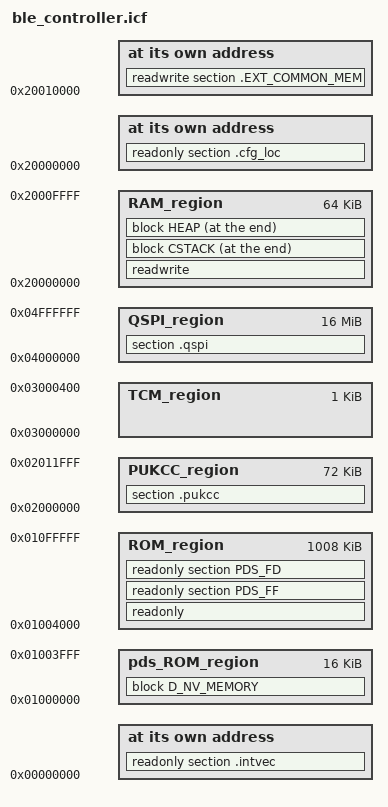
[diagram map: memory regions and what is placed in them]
/**
 * \file
 *
 * \brief Linker script for running in internal SRAM on the Liberty
 *
 * Copyright (c) 2017 Atmel Corporation,
 *                    a wholly owned subsidiary of Microchip Technology Inc.
 *
 * \asf_license_start
 *
 * \page License
 *
 * Licensed under the Apache License, Version 2.0 (the "License");
 * you may not use this file except in compliance with the License.
 * You may obtain a copy of the Licence at
 *
 *     http://www.apache.org/licenses/LICENSE-2.0
 *
 * Unless required by applicable law or agreed to in writing, software
 * distributed under the License is distributed on an "AS IS" BASIS,
 * WITHOUT WARRANTIES OR CONDITIONS OF ANY KIND, either express or implied.
 * See the License for the specific language governing permissions and
 * limitations under the License.
 *
 * \asf_license_stop
 *
 */

/*###ICF### Section handled by ICF editor, don't touch! ****/
/*-Editor annotation file-*/
/* IcfEditorFile="$TOOLKIT_DIR$\config\ide\IcfEditor\cortex_v1_0.xml" */
/*-Specials-*/
define symbol __ICFEDIT_intvec_start__ = 0x00000000;
/*-Memory Regions-*/
define symbol __ICFEDIT_region_RAM_start__           = 0x20000000;
define symbol __ICFEDIT_region_RAM_end__             = 0x2000FFFF;
define symbol __ICFEDIT_region_EXT_COMMON_MEM_start_ = 0x20010000;
define symbol __ICFEDIT_region_PUKCC_start__         = 0x02000000;
define symbol __ICFEDIT_region_PUKCC_end__           = 0x02011FFF;
define symbol __ICFEDIT_region_QSPI_start__          = 0x04000000;
define symbol __ICFEDIT_region_QSPI_end__            = 0x04FFFFFF;
define symbol __ICFEDIT_region_pds_ROM_start__       = 0x1000000;
define symbol __ICFEDIT_region_pds_ROM_end__         = 0x1003FFF;
//define symbol __ICFEDIT_region_ROM0_start__          = 0x00000000;
//define symbol __ICFEDIT_region_ROM0_end__            = 0x00004FFF;
define symbol __ICFEDIT_region_ROM1_start__          = 0x01004000;
define symbol __ICFEDIT_region_ROM1_end__            = 0x010FFFFF;
define symbol __ICFEDIT_region_TCM_start__           = 0x03000000;
define symbol __ICFEDIT_region_TCM_end__             = 0x03000400;
/*-Sizes-*/
if (!isdefinedsymbol(__ICFEDIT_size_cstack__)) {
define symbol __ICFEDIT_size_cstack__ = 512;
}
if (!isdefinedsymbol(__ICFEDIT_size_heap__)) {
define symbol __ICFEDIT_size_heap__     = 0;
}
define symbol D_NV_MEMORY_START = 0x01000000;
define symbol _D_NV_MEMORY_SIZE = 0x4000; 


/**** End of ICF editor section. ###ICF###*/

define memory mem with size = 4G;
define region RAM_region    = mem:[from __ICFEDIT_region_RAM_start__ to __ICFEDIT_region_RAM_end__];
define region PUKCC_region  = mem:[from __ICFEDIT_region_PUKCC_start__ to __ICFEDIT_region_PUKCC_end__];
define region QSPI_region   = mem:[from __ICFEDIT_region_QSPI_start__ to __ICFEDIT_region_QSPI_end__];
define region pds_ROM_region = mem:[from __ICFEDIT_region_pds_ROM_start__ to __ICFEDIT_region_pds_ROM_end__];
define region ROM_region    = mem:[from __ICFEDIT_region_ROM1_start__ to __ICFEDIT_region_ROM1_end__];
define region TCM_region    = mem:[from __ICFEDIT_region_TCM_start__ to __ICFEDIT_region_TCM_end__];

define block CSTACK with alignment = 8, size = __ICFEDIT_size_cstack__ { };
define block HEAP   with alignment = 8, size = __ICFEDIT_size_heap__   { };
define block D_NV_MEMORY with size = _D_NV_MEMORY_SIZE, alignment = 8 { };

initialize by copy  { readwrite };
do not initialize   { section .noinit };

initialize manually { section .qspi };

place at address mem:__ICFEDIT_region_EXT_COMMON_MEM_start_ { readwrite section .EXT_COMMON_MEM };
place at address mem:__ICFEDIT_region_RAM_start__ { readonly section .cfg_loc };
place at address mem:__ICFEDIT_intvec_start__ { readonly section .intvec };
place in ROM_region                           { readonly };
place in RAM_region                           { readwrite };
place in ROM_region                      { readonly section PDS_FF};    /* PDS files descriptors segment */
place in ROM_region                      { readonly section PDS_FD};  
place in pds_ROM_region                       { block D_NV_MEMORY };
place at end of RAM_region                    { block CSTACK, block HEAP };
place in PUKCC_region                         { section .pukcc };
place in QSPI_region                          { section .qspi };
